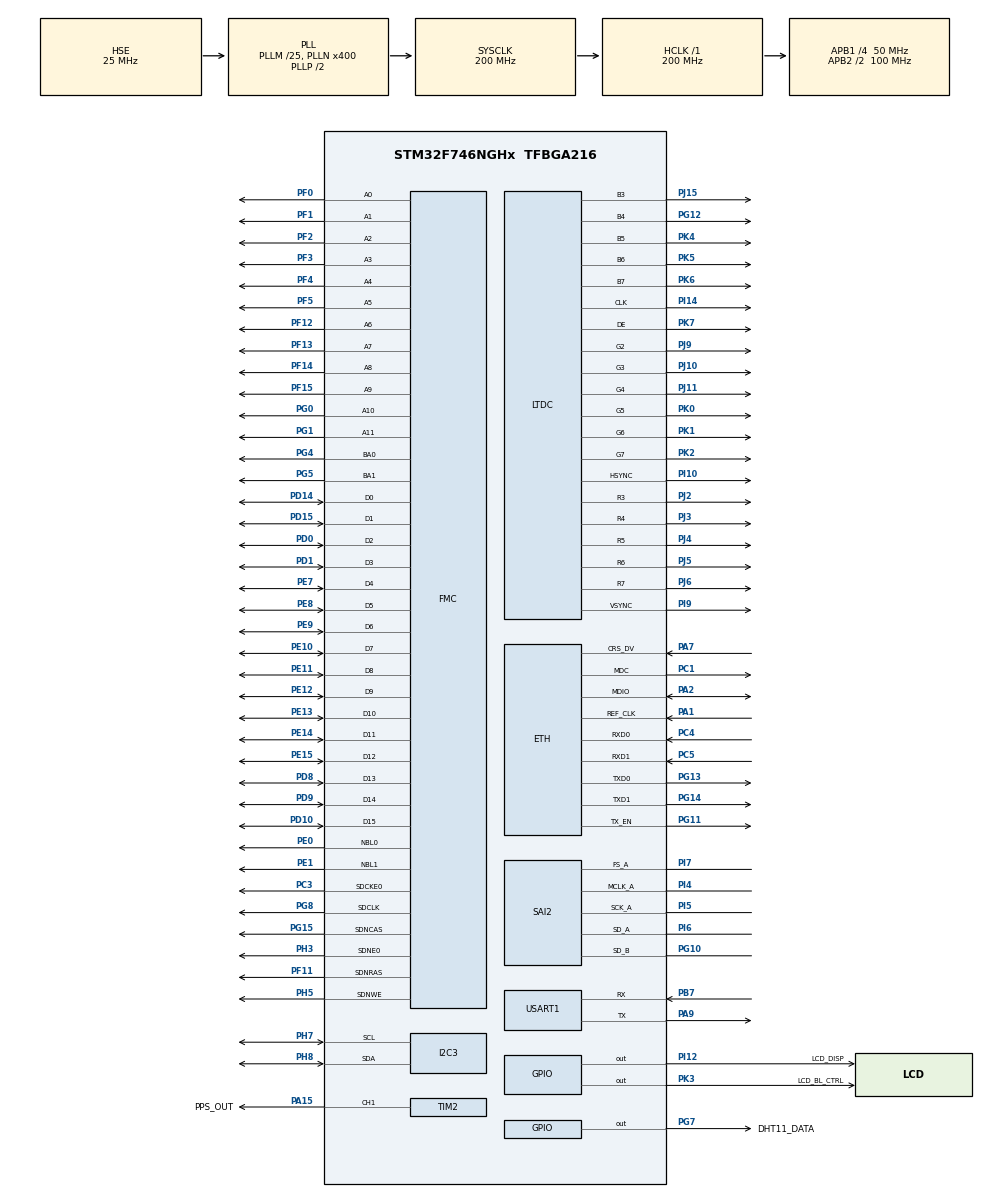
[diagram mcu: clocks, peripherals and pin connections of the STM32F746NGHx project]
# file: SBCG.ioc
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CORTEX_M7.AccessPermission_S-Cortex_Memory_Protection_Unit_Region1_Settings_S=MPU_REGION_FULL_ACCESS
CORTEX_M7.AccessPermission_S-Cortex_Memory_Protection_Unit_Region2_Settings_S=MPU_REGION_FULL_ACCESS
CORTEX_M7.BaseAddress_S-Cortex_Memory_Protection_Unit_Region1_Settings_S=0xC0000000
CORTEX_M7.BaseAddress_S-Cortex_Memory_Protection_Unit_Region2_Settings_S=0xA0000000
CORTEX_M7.DisableExec_S-Cortex_Memory_Protection_Unit_Region1_Settings_S=MPU_INSTRUCTION_ACCESS_DISABLE
CORTEX_M7.DisableExec_S-Cortex_Memory_Protection_Unit_Region2_Settings_S=MPU_INSTRUCTION_ACCESS_DISABLE
CORTEX_M7.Enable_S-Cortex_Memory_Protection_Unit_Region1_Settings_S=MPU_REGION_ENABLE
CORTEX_M7.Enable_S-Cortex_Memory_Protection_Unit_Region2_Settings_S=MPU_REGION_ENABLE
CORTEX_M7.IsBufferable_S-Cortex_Memory_Protection_Unit_Region2_Settings_S=MPU_ACCESS_BUFFERABLE
CORTEX_M7.IsShareable_S-Cortex_Memory_Protection_Unit_Region2_Settings_S=MPU_ACCESS_SHAREABLE
CORTEX_M7.Size_S-Cortex_Memory_Protection_Unit_Region1_Settings_S=MPU_REGION_SIZE_8MB
CORTEX_M7.Size_S-Cortex_Memory_Protection_Unit_Region2_Settings_S=MPU_REGION_SIZE_4KB
CORTEX_M7.TypeExtField_S-Cortex_Memory_Protection_Unit_Region1_Settings_S=MPU_TEX_LEVEL1
CORTEX_M7.default_mode_Activation=1
Dma.Request0=SAI2_B
Dma.Request1=USART1_TX
Dma.SAI2_B.0.Direction=DMA_PERIPH_TO_MEMORY
Dma.SAI2_B.0.FIFOMode=DMA_FIFOMODE_DISABLE
Dma.SAI2_B.0.Instance=DMA2_Stream6
Dma.SAI2_B.0.MemDataAlignment=DMA_MDATAALIGN_HALFWORD
Dma.SAI2_B.0.MemInc=DMA_MINC_ENABLE
Dma.SAI2_B.0.Mode=DMA_CIRCULAR
Dma.SAI2_B.0.PeriphDataAlignment=DMA_PDATAALIGN_HALFWORD
Dma.SAI2_B.0.PeriphInc=DMA_PINC_DISABLE
Dma.SAI2_B.0.Priority=DMA_PRIORITY_HIGH
Dma.USART1_TX.1.Direction=DMA_MEMORY_TO_PERIPH
Dma.USART1_TX.1.FIFOMode=DMA_FIFOMODE_DISABLE
Dma.USART1_TX.1.Instance=DMA2_Stream7
Dma.USART1_TX.1.MemDataAlignment=DMA_MDATAALIGN_BYTE
Dma.USART1_TX.1.MemInc=DMA_MINC_ENABLE
Dma.USART1_TX.1.Mode=DMA_NORMAL
Dma.USART1_TX.1.PeriphDataAlignment=DMA_PDATAALIGN_BYTE
Dma.USART1_TX.1.PeriphInc=DMA_PINC_DISABLE
Dma.USART1_TX.1.Priority=DMA_PRIORITY_LOW
ETH.MACAddr=02\:00\:00\:00\:00\:01
ETH.MediaInterface=HAL_ETH_RMII_MODE
ETH.RxBuffLen=1536
ETH.RxDescAddress=0x2004C0A0
ETH.TxDescAddress=0x2004C000
FMC.CASLatency1=FMC_SDRAM_CAS_LATENCY_3
FMC.ExitSelfRefreshDelay1=8
FMC.LoadToActiveDelay1=2
FMC.RCDDelay1=2
FMC.RPDelay1=2
FMC.ReadBurst1=FMC_SDRAM_RBURST_ENABLE
FMC.ReadPipeDelay1=FMC_SDRAM_RPIPE_DELAY_0
FMC.RowCycleDelay1=7
FMC.SDClockPeriod1=FMC_SDRAM_CLOCK_PERIOD_3
FMC.SelfRefreshTime1=5
FMC.WriteRecoveryTime1=3
I2C3.Timing=0x00C0EAFF
LTDC.ActiveH=272
LTDC.ActiveW=480
LTDC.Alpha_L0=255
LTDC.FBStartAdress_L0=0xC0000000
LTDC.HBP=13
LTDC.HFP=32
LTDC.HSync=41
LTDC.ImageHeight_L0=272
LTDC.ImageWidth_L0=480
LTDC.Layers=0
LTDC.PixelFormat_L0=LTDC_PIXEL_FORMAT_RGB565
LTDC.VSync=10
LTDC.WindowX1_L0=480
LTDC.WindowY1_L0=272
LWIP.BSP.number=1
LWIP.ETH_RX_BUFFER_CNT=4
LWIP.IP_ADDRESS=192.168.010.001
LWIP.LWIP_DHCP=0
LWIP.LWIP_TCP=0
LWIP.MEMP_NUM_UDP_PCB=10
LWIP.MEM_SIZE=4096
LWIP.NETMASK_ADDRESS=255.255.255.000
LWIP.Version=v2.1.2_Cube
LWIP0.BSP.STBoard=false
LWIP0.BSP.api=BSP_COMPONENT_DRIVER
LWIP0.BSP.component=LAN8742
LWIP0.BSP.instance=LAN8742
LWIP0.BSP.name=Driver_PHY
LWIP0.BSP.semaphore=S_LAN8742
LWIP0.BSP.solution=LAN8742
Mcu.Family=STM32F7
Mcu.Name=STM32F746NGHx
Mcu.Package=TFBGA216
NVIC.DMA2_Stream6_IRQn=true\:4\:0\:false\:false\:true\:false\:true\:true
NVIC.DMA2_Stream7_IRQn=true\:6\:0\:true\:false\:true\:false\:true\:true
NVIC.LTDC_IRQn=true\:9\:0\:true\:false\:true\:true\:true\:true
NVIC.PriorityGroup=NVIC_PRIORITYGROUP_4
NVIC.SAI2_IRQn=true\:4\:0\:true\:false\:true\:true\:true\:true
NVIC.USART1_IRQn=true\:5\:0\:true\:false\:true\:true\:true\:true
PA1.Mode=RMII
PA1.Signal=ETH_REF_CLK
PA13.Mode=Trace_Asynchronous_SW
PA13.Signal=SYS_JTMS-SWDIO
PA14.Mode=Trace_Asynchronous_SW
PA14.Signal=SYS_JTCK-SWCLK
PA15.GPIO_Label=PPS_OUT
PA15.GPIO_PuPd=GPIO_PULLDOWN
PA15.Signal=S_TIM2_CH1_ETR
PA2.Mode=RMII
PA2.Signal=ETH_MDIO
PA7.Mode=RMII
PA7.Signal=ETH_CRS_DV
PA9.Mode=Asynchronous
PA9.Signal=USART1_TX
PB3.Mode=Trace_Asynchronous_SW
PB3.Signal=SYS_JTDO-SWO
PB7.Mode=Asynchronous
PB7.Signal=USART1_RX
PC1.Mode=RMII
PC1.Signal=ETH_MDC
PC3.Mode=SdramChipSelect1_1
PC3.Signal=FMC_SDCKE0
PC4.Mode=RMII
PC4.Signal=ETH_RXD0
PC5.Mode=RMII
PC5.Signal=ETH_RXD1
PD0.Signal=FMC_D2_DA2
PD1.Signal=FMC_D3_DA3
PD10.Signal=FMC_D15_DA15
PD14.Signal=FMC_D0_DA0
PD15.Signal=FMC_D1_DA1
PD8.Signal=FMC_D13_DA13
PD9.Signal=FMC_D14_DA14
PE0.Signal=FMC_NBL0
PE1.Signal=FMC_NBL1
PE10.Signal=FMC_D7_DA7
PE11.Signal=FMC_D8_DA8
PE12.Signal=FMC_D9_DA9
PE13.Signal=FMC_D10_DA10
PE14.Signal=FMC_D11_DA11
PE15.Signal=FMC_D12_DA12
PE7.Signal=FMC_D4_DA4
PE8.Signal=FMC_D5_DA5
PE9.Signal=FMC_D6_DA6
PF0.Signal=FMC_A0
PF1.Signal=FMC_A1
PF11.Signal=FMC_SDNRAS
PF12.Signal=FMC_A6
PF13.Signal=FMC_A7
PF14.Signal=FMC_A8
PF15.Signal=FMC_A9
PF2.Signal=FMC_A2
PF3.Signal=FMC_A3
PF4.Signal=FMC_A4
PF5.Signal=FMC_A5
PG0.Signal=FMC_A10
PG1.Signal=FMC_A11
PG10.GPIO_Speed=GPIO_SPEED_FREQ_HIGH
PG10.Mode=SAI_B_SyncSlave
PG10.Signal=SAI2_SD_B
PG11.Mode=RMII
PG11.Signal=ETH_TX_EN
PG12.GPIO_Speed=GPIO_SPEED_FREQ_VERY_HIGH
PG12.Mode=RGB565
PG12.Signal=LTDC_B4
PG13.Mode=RMII
PG13.Signal=ETH_TXD0
PG14.Mode=RMII
PG14.Signal=ETH_TXD1
PG15.Signal=FMC_SDNCAS
PG4.Signal=FMC_A14_BA0
PG5.Signal=FMC_A15_BA1
PG7.GPIO_Label=DHT11_DATA
PG7.GPIO_ModeDefaultOutputPP=GPIO_MODE_OUTPUT_OD
PG7.GPIO_PuPd=GPIO_NOPULL
PG7.PinState=GPIO_PIN_SET
PG7.Signal=GPIO_Output
PG8.Signal=FMC_SDCLK
PH0/OSC_IN.Mode=HSE-External-Clock-Source
PH0/OSC_IN.Signal=RCC_OSC_IN
PH1/OSC_OUT.Mode=HSE-External-Clock-Source
PH1/OSC_OUT.Signal=RCC_OSC_OUT
PH3.Mode=SdramChipSelect1_1
PH3.Signal=FMC_SDNE0
PH5.Signal=FMC_SDNWE
PH7.Mode=I2C
PH7.Signal=I2C3_SCL
PH8.Mode=I2C
PH8.Signal=I2C3_SDA
PI10.GPIO_Speed=GPIO_SPEED_FREQ_VERY_HIGH
PI10.Mode=RGB565
PI10.Signal=LTDC_HSYNC
PI12.GPIO_Label=LCD_DISP
PI12.Signal=GPIO_Output
PI14.GPIO_Speed=GPIO_SPEED_FREQ_VERY_HIGH
PI14.Mode=RGB565
PI14.Signal=LTDC_CLK
PI4.GPIO_Speed=GPIO_SPEED_FREQ_VERY_HIGH
PI4.Mode=SAI_A_MasterWithClock
PI4.Signal=SAI2_MCLK_A
PI5.GPIO_Speed=GPIO_SPEED_FREQ_VERY_HIGH
PI5.Mode=SAI_A_MasterWithClock
PI5.Signal=SAI2_SCK_A
PI6.GPIO_Speed=GPIO_SPEED_FREQ_VERY_HIGH
PI6.Mode=SAI_A_MasterWithClock
PI6.Signal=SAI2_SD_A
PI7.GPIO_Speed=GPIO_SPEED_FREQ_VERY_HIGH
PI7.Mode=SAI_A_MasterWithClock
PI7.Signal=SAI2_FS_A
PI9.GPIO_Speed=GPIO_SPEED_FREQ_VERY_HIGH
PI9.Mode=RGB565
PI9.Signal=LTDC_VSYNC
PJ10.GPIO_Speed=GPIO_SPEED_FREQ_VERY_HIGH
PJ10.Mode=RGB565
PJ10.Signal=LTDC_G3
PJ11.GPIO_Speed=GPIO_SPEED_FREQ_VERY_HIGH
PJ11.Mode=RGB565
PJ11.Signal=LTDC_G4
PJ15.GPIO_Speed=GPIO_SPEED_FREQ_VERY_HIGH
PJ15.Mode=RGB565
PJ15.Signal=LTDC_B3
PJ2.GPIO_Speed=GPIO_SPEED_FREQ_VERY_HIGH
PJ2.Mode=RGB565
PJ2.Signal=LTDC_R3
PJ3.GPIO_Speed=GPIO_SPEED_FREQ_VERY_HIGH
PJ3.Mode=RGB565
PJ3.Signal=LTDC_R4
PJ4.GPIO_Speed=GPIO_SPEED_FREQ_VERY_HIGH
PJ4.Mode=RGB565
PJ4.Signal=LTDC_R5
PJ5.GPIO_Speed=GPIO_SPEED_FREQ_VERY_HIGH
PJ5.Mode=RGB565
PJ5.Signal=LTDC_R6
PJ6.GPIO_Speed=GPIO_SPEED_FREQ_VERY_HIGH
PJ6.Mode=RGB565
PJ6.Signal=LTDC_R7
PJ9.GPIO_Speed=GPIO_SPEED_FREQ_VERY_HIGH
PJ9.Mode=RGB565
PJ9.Signal=LTDC_G2
PK0.GPIO_Speed=GPIO_SPEED_FREQ_VERY_HIGH
PK0.Mode=RGB565
PK0.Signal=LTDC_G5
PK1.GPIO_Speed=GPIO_SPEED_FREQ_VERY_HIGH
PK1.Mode=RGB565
PK1.Signal=LTDC_G6
PK2.GPIO_Speed=GPIO_SPEED_FREQ_VERY_HIGH
PK2.Mode=RGB565
PK2.Signal=LTDC_G7
PK3.GPIO_Label=LCD_BL_CTRL
PK3.Signal=GPIO_Output
PK4.GPIO_Speed=GPIO_SPEED_FREQ_VERY_HIGH
PK4.Mode=RGB565
PK4.Signal=LTDC_B5
PK5.GPIO_Speed=GPIO_SPEED_FREQ_VERY_HIGH
PK5.Mode=RGB565
PK5.Signal=LTDC_B6
PK6.GPIO_Speed=GPIO_SPEED_FREQ_VERY_HIGH
PK6.Mode=RGB565
PK6.Signal=LTDC_B7
PK7.GPIO_Speed=GPIO_SPEED_FREQ_VERY_HIGH
PK7.Mode=RGB565
PK7.Signal=LTDC_DE
ProjectManager.HeapSize=0x200
ProjectManager.StackSize=0x400
ProjectManager.TargetToolchain=CMake
RCC.AHBFreq_Value=200000000
RCC.APB1CLKDivider=RCC_HCLK_DIV4
RCC.APB1Freq_Value=50000000
RCC.APB1TimFreq_Value=100000000
RCC.APB2CLKDivider=RCC_HCLK_DIV2
RCC.APB2Freq_Value=100000000
RCC.APB2TimFreq_Value=200000000
RCC.CortexFreq_Value=200000000
RCC.HCLKFreq_Value=200000000
RCC.HSE_VALUE=25000000
RCC.HSI_VALUE=16000000
RCC.LSE_VALUE=32768
RCC.PLLI2SN=344
RCC.PLLI2SQ=7
RCC.PLLM=25
RCC.PLLN=400
RCC.PLLSAIR=5
RCC.PLLSAIRDiv=RCC_PLLSAIDIVR_4
RCC.PLLSourceVirtual=RCC_PLLSOURCE_HSE
RCC.SAI2CLockSelection=RCC_SAI2CLKSOURCE_PLLI2S
RCC.SYSCLKFreq_VALUE=200000000
RCC.SYSCLKSource=RCC_SYSCLKSOURCE_PLLCLK
RCC.USBFreq_Value=200000000
RCC.VCOOutputFreq_Value=400000000
SAI2.ActiveFrameLength-SAI_A_MasterWithClock=32
SAI2.ActiveFrameLength-SAI_B_SyncSlave=32
SAI2.AudioFrequency-SAI_A_MasterWithClock=SAI_AUDIO_FREQUENCY_48K
SAI2.AudioMode-SAI_A_MasterWithClock=SAI_MODEMASTER_RX
SAI2.ClockStrobing-SAI_A_MasterWithClock=SAI_CLOCKSTROBING_RISINGEDGE
SAI2.ClockStrobing-SAI_B_SyncSlave=SAI_CLOCKSTROBING_RISINGEDGE
SAI2.DataSize-SAI_A_MasterWithClock=SAI_DATASIZE_16
SAI2.DataSize-SAI_B_SyncSlave=SAI_DATASIZE_16
SAI2.ErrorAudioFreq-SAI_A_MasterWithClock=-0.01 %
SAI2.FIFOThreshold-SAI_A_MasterWithClock=SAI_FIFOTHRESHOLD_1QF
SAI2.FIFOThreshold-SAI_B_SyncSlave=SAI_FIFOTHRESHOLD_1QF
SAI2.FSDefinition-SAI_A_MasterWithClock=SAI_FS_CHANNEL_IDENTIFICATION
SAI2.FSDefinition-SAI_B_SyncSlave=SAI_FS_CHANNEL_IDENTIFICATION
SAI2.FSOffset-SAI_A_MasterWithClock=SAI_FS_BEFOREFIRSTBIT
SAI2.FSOffset-SAI_B_SyncSlave=SAI_FS_BEFOREFIRSTBIT
SAI2.FrameLength-SAI_A_MasterWithClock=64
SAI2.FrameLength-SAI_B_SyncSlave=64
SAI2.Instance-SAI_A_MasterWithClock=SAI$Index_Block_A
SAI2.Instance-SAI_B_SyncSlave=SAI$Index_Block_B
SAI2.MClockEnable-SAI_A_MasterWithClock=SAI_MASTERCLOCK_ENABLE
SAI2.OutputDrive-SAI_A_MasterWithClock=SAI_OUTPUTDRIVE_ENABLE
SAI2.RealAudioFreq-SAI_A_MasterWithClock=47.991 KHz
SAI2.SlotActive-SAI_A_MasterWithClock=0x0000000A
SAI2.SlotActive-SAI_B_SyncSlave=0x0000000A
SAI2.SlotNumber-SAI_A_MasterWithClock=4
SAI2.SlotNumber-SAI_B_SyncSlave=4
SAI2.VirtualMode-SAI_A_MasterWithClock=VM_MASTER
SAI2.VirtualMode-SAI_B_SyncSlave=VM_SLAVE
SAI2.VirtualSlotActive-SAI_A_MasterWithClock=SAI_SLOT_USERSETTING
SAI2.VirtualSlotActive-SAI_B_SyncSlave=SAI_SLOT_USERSETTING
SAI2.VirtualSlotActive0-SAI_B_SyncSlave=false
SAI2.VirtualSlotActive1-SAI_A_MasterWithClock=true
SAI2.VirtualSlotActive1-SAI_B_SyncSlave=true
SAI2.VirtualSlotActive2-SAI_B_SyncSlave=false
SAI2.VirtualSlotActive3-SAI_A_MasterWithClock=true
SAI2.VirtualSlotActive3-SAI_B_SyncSlave=true
SH.FMC_A0.0=FMC_A0,12b-sda1
SH.FMC_A1.0=FMC_A1,12b-sda1
SH.FMC_A10.0=FMC_A10,12b-sda1
SH.FMC_A11.0=FMC_A11,12b-sda1
SH.FMC_A14_BA0.0=FMC_BA0,FourSdramBanks1
SH.FMC_A15_BA1.0=FMC_BA1,FourSdramBanks1
SH.FMC_A2.0=FMC_A2,12b-sda1
SH.FMC_A3.0=FMC_A3,12b-sda1
SH.FMC_A4.0=FMC_A4,12b-sda1
SH.FMC_A5.0=FMC_A5,12b-sda1
SH.FMC_A6.0=FMC_A6,12b-sda1
SH.FMC_A7.0=FMC_A7,12b-sda1
SH.FMC_A8.0=FMC_A8,12b-sda1
SH.FMC_A9.0=FMC_A9,12b-sda1
SH.FMC_D0_DA0.0=FMC_D0,sd-16b-d1
SH.FMC_D10_DA10.0=FMC_D10,sd-16b-d1
SH.FMC_D11_DA11.0=FMC_D11,sd-16b-d1
SH.FMC_D12_DA12.0=FMC_D12,sd-16b-d1
SH.FMC_D13_DA13.0=FMC_D13,sd-16b-d1
SH.FMC_D14_DA14.0=FMC_D14,sd-16b-d1
SH.FMC_D15_DA15.0=FMC_D15,sd-16b-d1
SH.FMC_D1_DA1.0=FMC_D1,sd-16b-d1
SH.FMC_D2_DA2.0=FMC_D2,sd-16b-d1
SH.FMC_D3_DA3.0=FMC_D3,sd-16b-d1
SH.FMC_D4_DA4.0=FMC_D4,sd-16b-d1
SH.FMC_D5_DA5.0=FMC_D5,sd-16b-d1
SH.FMC_D6_DA6.0=FMC_D6,sd-16b-d1
SH.FMC_D7_DA7.0=FMC_D7,sd-16b-d1
SH.FMC_D8_DA8.0=FMC_D8,sd-16b-d1
SH.FMC_D9_DA9.0=FMC_D9,sd-16b-d1
SH.FMC_NBL0.0=FMC_NBL0,Sd2ByteEnable1
SH.FMC_NBL1.0=FMC_NBL1,Sd2ByteEnable1
SH.FMC_SDCLK.0=FMC_SDCLK,12b-sda1
SH.FMC_SDNCAS.0=FMC_SDNCAS,12b-sda1
SH.FMC_SDNRAS.0=FMC_SDNRAS,12b-sda1
SH.FMC_SDNWE.0=FMC_SDNWE,12b-sda1
SH.S_TIM2_CH1_ETR.0=TIM2_CH1,PWM Generation1 CH1
STMicroelectronics.X-CUBE-TOUCHGFX.4.26.1.ApplicationCcGraphicsJjApplication=TouchGFXOoGenerator
STMicroelectronics.X-CUBE-TOUCHGFX.4.26.1.tgfx_address1=0xC0000000
STMicroelectronics.X-CUBE-TOUCHGFX.4.26.1.tgfx_address2=0xC0040000
STMicroelectronics.X-CUBE-TOUCHGFX.4.26.1.tgfx_buffering_strategy=Double
STMicroelectronics.X-CUBE-TOUCHGFX.4.26.1.tgfx_display_interface=disp_ltdc
STMicroelectronics.X-CUBE-TOUCHGFX.4.26.1.tgfx_location=By Address
STMicroelectronics.X-CUBE-TOUCHGFX.4.26.1.tgfx_vsync=vsync_ltdc
STMicroelectronics.X-CUBE-TOUCHGFX.4.26.1_IsPackSelfContextualization=true
TIM2.Channel-PWM\ Generation1\ CH1=TIM_CHANNEL_1
TIM2.Prescaler=99
TIM2.Pulse-PWM\ Generation1\ CH1=100
TIM2.TIM2_ITR1_REMAP=TIM_TIM2_ETH_PTP
TIM2.TIM_MasterSlaveMode=TIM_MASTERSLAVEMODE_ENABLE
USART1.VirtualMode-Asynchronous=VM_ASYNC
VP_CRC_VS_CRC.Mode=CRC_Activate
VP_LWIP_VS_Enabled.Mode=Enabled
VP_STMicroelectronics.X-CUBE-TOUCHGFX_VS_GraphicsJjApplication_4.26.1.Mode=GraphicsJjApplication
VP_TIM2_VS_ClockSourceINT.Mode=Internal
VP_TIM2_VS_ClockSourceITR.Mode=TriggerSource_ITR1
VP_TIM2_VS_ControllerModeReset.Mode=Reset Mode
board=custom

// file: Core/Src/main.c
/* USER CODE BEGIN Header */
/**
  ******************************************************************************
  * @file           : main.c
  * @brief          : Main program body
  ******************************************************************************
  * @attention
  *
  * Copyright (c) 2026 STMicroelectronics.
  * All rights reserved.
  *
  * This software is licensed under terms that can be found in the LICENSE file
  * in the root directory of this software component.
  * If no LICENSE file comes with this software, it is provided AS-IS.
  *
  ******************************************************************************
  */
/* USER CODE END Header */
#include "main.h"
#include "lwip.h"
#include "app_touchgfx.h"

/* USER CODE BEGIN Includes */
#include "app_main.h"
#ifdef SBCG_STACK_DIAGNOSTIC
#include "BSP/bsp_stack_diag.h"
#endif
#ifdef SBCG_USE_RESET_DIAGNOSTIC
#include "BSP/bsp_reset.h"
#endif
/* USER CODE END Includes */

CRC_HandleTypeDef hcrc;

I2C_HandleTypeDef hi2c3;

LTDC_HandleTypeDef hltdc;

SAI_HandleTypeDef hsai_BlockA2;
SAI_HandleTypeDef hsai_BlockB2;
DMA_HandleTypeDef hdma_sai2_b;

TIM_HandleTypeDef htim2;

UART_HandleTypeDef huart1;
DMA_HandleTypeDef hdma_usart1_tx;

SDRAM_HandleTypeDef hsdram1;

void SystemClock_Config(void);
void PeriphCommonClock_Config(void);
static void MPU_Config(void);
static void MX_GPIO_Init(void);
static void MX_DMA_Init(void);
static void MX_USART1_UART_Init(void);
static void MX_I2C3_Init(void);
static void MX_SAI2_Init(void);
static void MX_TIM2_Init(void);
static void MX_FMC_Init(void);
static void MX_CRC_Init(void);

int main(void)
{

  /* USER CODE BEGIN 1 */
#ifdef SBCG_STACK_DIAGNOSTIC
  /* 在HAL启动中断前涂写MSP预留区，跳过当前main栈帧。 */
  BSP_StackDiag_Paint();
#endif
#ifdef SBCG_USE_RESET_DIAGNOSTIC
  /* 在HAL/时钟初始化前保存并清除累计复位状态，不改变时钟或引脚配置。 */
  BSP_Reset_Capture();
#endif
  /* USER CODE END 1 */

  /* MPU Configuration--------------------------------------------------------*/
  MPU_Config();

  /* MCU Configuration--------------------------------------------------------*/

  /* Reset of all peripherals, Initializes the Flash interface and the Systick. */
  HAL_Init();

  /* Configure the system clock */
  SystemClock_Config();

  /* Configure the peripherals common clocks */
  PeriphCommonClock_Config();

  /* Initialize all configured peripherals */
  MX_GPIO_Init();
  MX_DMA_Init();
  MX_USART1_UART_Init();
  MX_I2C3_Init();
  MX_LWIP_Init();
  MX_SAI2_Init();
  MX_TIM2_Init();
  MX_FMC_Init();
  MX_CRC_Init();
  /* USER CODE BEGIN 2 */
  App_Init();
  /* USER CODE END 2 */

  /* Infinite loop */
  while (1)
  {

  MX_TouchGFX_Process();
    /* USER CODE BEGIN 3 */
    App_Process();
  }
  /* USER CODE END 3 */
}

void SystemClock_Config(void)
{
  RCC_OscInitTypeDef RCC_OscInitStruct = {0};
  RCC_ClkInitTypeDef RCC_ClkInitStruct = {0};

  /** Configure the main internal regulator output voltage
  */
  __HAL_RCC_PWR_CLK_ENABLE();
  __HAL_PWR_VOLTAGESCALING_CONFIG(PWR_REGULATOR_VOLTAGE_SCALE1);

  /** Initializes the RCC Oscillators according to the specified parameters
  * in the RCC_OscInitTypeDef structure.
  */
  RCC_OscInitStruct.OscillatorType = RCC_OSCILLATORTYPE_HSE;
  RCC_OscInitStruct.HSEState = RCC_HSE_BYPASS;
  RCC_OscInitStruct.PLL.PLLState = RCC_PLL_ON;
  RCC_OscInitStruct.PLL.PLLSource = RCC_PLLSOURCE_HSE;
  RCC_OscInitStruct.PLL.PLLM = 25;
  RCC_OscInitStruct.PLL.PLLN = 400;
  RCC_OscInitStruct.PLL.PLLP = RCC_PLLP_DIV2;
  RCC_OscInitStruct.PLL.PLLQ = 2;
  if (HAL_RCC_OscConfig(&RCC_OscInitStruct) != HAL_OK)
  {
    Error_Handler();
  }

  /** Activate the Over-Drive mode
  */
  if (HAL_PWREx_EnableOverDrive() != HAL_OK)
  {
    Error_Handler();
  }

  /** Initializes the CPU, AHB and APB buses clocks
  */
  RCC_ClkInitStruct.ClockType = RCC_CLOCKTYPE_HCLK|RCC_CLOCKTYPE_SYSCLK
                              |RCC_CLOCKTYPE_PCLK1|RCC_CLOCKTYPE_PCLK2;
  RCC_ClkInitStruct.SYSCLKSource = RCC_SYSCLKSOURCE_PLLCLK;
  RCC_ClkInitStruct.AHBCLKDivider = RCC_SYSCLK_DIV1;
  RCC_ClkInitStruct.APB1CLKDivider = RCC_HCLK_DIV4;
  RCC_ClkInitStruct.APB2CLKDivider = RCC_HCLK_DIV2;

  if (HAL_RCC_ClockConfig(&RCC_ClkInitStruct, FLASH_LATENCY_6) != HAL_OK)
  {
    Error_Handler();
  }
}

void PeriphCommonClock_Config(void)
{
  RCC_PeriphCLKInitTypeDef PeriphClkInitStruct = {0};

  /** Initializes the peripherals clock
  */
  PeriphClkInitStruct.PeriphClockSelection = RCC_PERIPHCLK_SAI2;
  PeriphClkInitStruct.PLLI2S.PLLI2SN = 344;
  PeriphClkInitStruct.PLLI2S.PLLI2SP = RCC_PLLP_DIV2;
  PeriphClkInitStruct.PLLI2S.PLLI2SR = 2;
  PeriphClkInitStruct.PLLI2S.PLLI2SQ = 7;
  PeriphClkInitStruct.PLLI2SDivQ = 1;
  PeriphClkInitStruct.Sai2ClockSelection = RCC_SAI2CLKSOURCE_PLLI2S;
  if (HAL_RCCEx_PeriphCLKConfig(&PeriphClkInitStruct) != HAL_OK)
  {
    Error_Handler();
  }
}

static void MX_CRC_Init(void)
{

  hcrc.Instance = CRC;
  hcrc.Init.DefaultPolynomialUse = DEFAULT_POLYNOMIAL_ENABLE;
  hcrc.Init.DefaultInitValueUse = DEFAULT_INIT_VALUE_ENABLE;
  hcrc.Init.InputDataInversionMode = CRC_INPUTDATA_INVERSION_NONE;
  hcrc.Init.OutputDataInversionMode = CRC_OUTPUTDATA_INVERSION_DISABLE;
  hcrc.InputDataFormat = CRC_INPUTDATA_FORMAT_BYTES;
  if (HAL_CRC_Init(&hcrc) != HAL_OK)
  {
    Error_Handler();
  }

}

static void MX_I2C3_Init(void)
{

  hi2c3.Instance = I2C3;
  hi2c3.Init.Timing = 0x00C0EAFF;
  hi2c3.Init.OwnAddress1 = 0;
  hi2c3.Init.AddressingMode = I2C_ADDRESSINGMODE_7BIT;
  hi2c3.Init.DualAddressMode = I2C_DUALADDRESS_DISABLE;
  hi2c3.Init.OwnAddress2 = 0;
  hi2c3.Init.OwnAddress2Masks = I2C_OA2_NOMASK;
  hi2c3.Init.GeneralCallMode = I2C_GENERALCALL_DISABLE;
  hi2c3.Init.NoStretchMode = I2C_NOSTRETCH_DISABLE;
  if (HAL_I2C_Init(&hi2c3) != HAL_OK)
  {
    Error_Handler();
  }

  /** Configure Analogue filter
  */
  if (HAL_I2CEx_ConfigAnalogFilter(&hi2c3, I2C_ANALOGFILTER_ENABLE) != HAL_OK)
  {
    Error_Handler();
  }

  /** Configure Digital filter
  */
  if (HAL_I2CEx_ConfigDigitalFilter(&hi2c3, 0) != HAL_OK)
  {
    Error_Handler();
  }

}

void MX_LTDC_Init(void)
{

  LTDC_LayerCfgTypeDef pLayerCfg = {0};

  hltdc.Instance = LTDC;
  hltdc.Init.HSPolarity = LTDC_HSPOLARITY_AL;
  hltdc.Init.VSPolarity = LTDC_VSPOLARITY_AL;
  hltdc.Init.DEPolarity = LTDC_DEPOLARITY_AL;
  hltdc.Init.PCPolarity = LTDC_PCPOLARITY_IPC;
  hltdc.Init.HorizontalSync = 40;
  hltdc.Init.VerticalSync = 9;
  hltdc.Init.AccumulatedHBP = 53;
  hltdc.Init.AccumulatedVBP = 11;
  hltdc.Init.AccumulatedActiveW = 533;
  hltdc.Init.AccumulatedActiveH = 283;
  hltdc.Init.TotalWidth = 565;
  hltdc.Init.TotalHeigh = 285;
  hltdc.Init.Backcolor.Blue = 0;
  hltdc.Init.Backcolor.Green = 0;
  hltdc.Init.Backcolor.Red = 0;
  if (HAL_LTDC_Init(&hltdc) != HAL_OK)
  {
    Error_Handler();
  }
  pLayerCfg.WindowX0 = 0;
  pLayerCfg.WindowX1 = 480;
  pLayerCfg.WindowY0 = 0;
  pLayerCfg.WindowY1 = 272;
  pLayerCfg.PixelFormat = LTDC_PIXEL_FORMAT_RGB565;
  pLayerCfg.Alpha = 255;
  pLayerCfg.Alpha0 = 0;
  pLayerCfg.BlendingFactor1 = LTDC_BLENDING_FACTOR1_CA;
  pLayerCfg.BlendingFactor2 = LTDC_BLENDING_FACTOR2_CA;
  pLayerCfg.FBStartAdress = 0xC0000000;
  pLayerCfg.ImageWidth = 480;
  pLayerCfg.ImageHeight = 272;
  pLayerCfg.Backcolor.Blue = 0;
  pLayerCfg.Backcolor.Green = 0;
  pLayerCfg.Backcolor.Red = 0;
  if (HAL_LTDC_ConfigLayer(&hltdc, &pLayerCfg, 0) != HAL_OK)
  {
    Error_Handler();
  }

}

static void MX_SAI2_Init(void)
{

  hsai_BlockA2.Instance = SAI2_Block_A;
  hsai_BlockA2.Init.Protocol = SAI_FREE_PROTOCOL;
  hsai_BlockA2.Init.AudioMode = SAI_MODEMASTER_RX;
  hsai_BlockA2.Init.DataSize = SAI_DATASIZE_16;
  hsai_BlockA2.Init.FirstBit = SAI_FIRSTBIT_MSB;
  hsai_BlockA2.Init.ClockStrobing = SAI_CLOCKSTROBING_RISINGEDGE;
  hsai_BlockA2.Init.Synchro = SAI_ASYNCHRONOUS;
  hsai_BlockA2.Init.OutputDrive = SAI_OUTPUTDRIVE_ENABLE;
  hsai_BlockA2.Init.NoDivider = SAI_MASTERDIVIDER_ENABLE;
  hsai_BlockA2.Init.FIFOThreshold = SAI_FIFOTHRESHOLD_1QF;
  hsai_BlockA2.Init.AudioFrequency = SAI_AUDIO_FREQUENCY_48K;
  hsai_BlockA2.Init.SynchroExt = SAI_SYNCEXT_DISABLE;
  hsai_BlockA2.Init.MonoStereoMode = SAI_STEREOMODE;
  hsai_BlockA2.Init.CompandingMode = SAI_NOCOMPANDING;
  hsai_BlockA2.FrameInit.FrameLength = 64;
  hsai_BlockA2.FrameInit.ActiveFrameLength = 32;
  hsai_BlockA2.FrameInit.FSDefinition = SAI_FS_CHANNEL_IDENTIFICATION;
  hsai_BlockA2.FrameInit.FSPolarity = SAI_FS_ACTIVE_LOW;
  hsai_BlockA2.FrameInit.FSOffset = SAI_FS_BEFOREFIRSTBIT;
  hsai_BlockA2.SlotInit.FirstBitOffset = 0;
  hsai_BlockA2.SlotInit.SlotSize = SAI_SLOTSIZE_DATASIZE;
  hsai_BlockA2.SlotInit.SlotNumber = 4;
  hsai_BlockA2.SlotInit.SlotActive = 0x0000000A;
  if (HAL_SAI_Init(&hsai_BlockA2) != HAL_OK)
  {
    Error_Handler();
  }
  hsai_BlockB2.Instance = SAI2_Block_B;
  hsai_BlockB2.Init.Protocol = SAI_FREE_PROTOCOL;
  hsai_BlockB2.Init.AudioMode = SAI_MODESLAVE_RX;
  hsai_BlockB2.Init.DataSize = SAI_DATASIZE_16;
  hsai_BlockB2.Init.FirstBit = SAI_FIRSTBIT_MSB;
  hsai_BlockB2.Init.ClockStrobing = SAI_CLOCKSTROBING_RISINGEDGE;
  hsai_BlockB2.Init.Synchro = SAI_SYNCHRONOUS;
  hsai_BlockB2.Init.OutputDrive = SAI_OUTPUTDRIVE_DISABLE;
  hsai_BlockB2.Init.FIFOThreshold = SAI_FIFOTHRESHOLD_1QF;
  hsai_BlockB2.Init.SynchroExt = SAI_SYNCEXT_DISABLE;
  hsai_BlockB2.Init.MonoStereoMode = SAI_STEREOMODE;
  hsai_BlockB2.Init.CompandingMode = SAI_NOCOMPANDING;
  hsai_BlockB2.Init.TriState = SAI_OUTPUT_NOTRELEASED;
  hsai_BlockB2.FrameInit.FrameLength = 64;
  hsai_BlockB2.FrameInit.ActiveFrameLength = 32;
  hsai_BlockB2.FrameInit.FSDefinition = SAI_FS_CHANNEL_IDENTIFICATION;
  hsai_BlockB2.FrameInit.FSPolarity = SAI_FS_ACTIVE_LOW;
  hsai_BlockB2.FrameInit.FSOffset = SAI_FS_BEFOREFIRSTBIT;
  hsai_BlockB2.SlotInit.FirstBitOffset = 0;
  hsai_BlockB2.SlotInit.SlotSize = SAI_SLOTSIZE_DATASIZE;
  hsai_BlockB2.SlotInit.SlotNumber = 4;
  hsai_BlockB2.SlotInit.SlotActive = 0x0000000A;
  if (HAL_SAI_Init(&hsai_BlockB2) != HAL_OK)
  {
    Error_Handler();
  }

}

static void MX_TIM2_Init(void)
{

  TIM_ClockConfigTypeDef sClockSourceConfig = {0};
  TIM_SlaveConfigTypeDef sSlaveConfig = {0};
  TIM_MasterConfigTypeDef sMasterConfig = {0};
  TIM_OC_InitTypeDef sConfigOC = {0};

  htim2.Instance = TIM2;
  htim2.Init.Prescaler = 99;
  htim2.Init.CounterMode = TIM_COUNTERMODE_UP;
  htim2.Init.Period = 4294967295;
  htim2.Init.ClockDivision = TIM_CLOCKDIVISION_DIV1;
  htim2.Init.AutoReloadPreload = TIM_AUTORELOAD_PRELOAD_DISABLE;
  if (HAL_TIM_Base_Init(&htim2) != HAL_OK)
  {
    Error_Handler();
  }
  sClockSourceConfig.ClockSource = TIM_CLOCKSOURCE_INTERNAL;
  if (HAL_TIM_ConfigClockSource(&htim2, &sClockSourceConfig) != HAL_OK)
  {
    Error_Handler();
  }
  if (HAL_TIM_PWM_Init(&htim2) != HAL_OK)
  {
    Error_Handler();
  }
  sSlaveConfig.SlaveMode = TIM_SLAVEMODE_RESET;
  sSlaveConfig.InputTrigger = TIM_TS_ITR1;
  if (HAL_TIM_SlaveConfigSynchro(&htim2, &sSlaveConfig) != HAL_OK)
  {
    Error_Handler();
  }
  sMasterConfig.MasterOutputTrigger = TIM_TRGO_RESET;
  sMasterConfig.MasterSlaveMode = TIM_MASTERSLAVEMODE_ENABLE;
  if (HAL_TIMEx_MasterConfigSynchronization(&htim2, &sMasterConfig) != HAL_OK)
  {
    Error_Handler();
  }
  if (HAL_TIMEx_RemapConfig(&htim2, TIM_TIM2_ETH_PTP) != HAL_OK)
  {
    Error_Handler();
  }
  sConfigOC.OCMode = TIM_OCMODE_PWM1;
  sConfigOC.Pulse = 100;
  sConfigOC.OCPolarity = TIM_OCPOLARITY_HIGH;
  sConfigOC.OCFastMode = TIM_OCFAST_DISABLE;
  if (HAL_TIM_PWM_ConfigChannel(&htim2, &sConfigOC, TIM_CHANNEL_1) != HAL_OK)
  {
    Error_Handler();
  }
  HAL_TIM_MspPostInit(&htim2);

}

static void MX_USART1_UART_Init(void)
{

  huart1.Instance = USART1;
  huart1.Init.BaudRate = 115200;
  huart1.Init.WordLength = UART_WORDLENGTH_8B;
  huart1.Init.StopBits = UART_STOPBITS_1;
  huart1.Init.Parity = UART_PARITY_NONE;
  huart1.Init.Mode = UART_MODE_TX_RX;
  huart1.Init.HwFlowCtl = UART_HWCONTROL_NONE;
  huart1.Init.OverSampling = UART_OVERSAMPLING_16;
  huart1.Init.OneBitSampling = UART_ONE_BIT_SAMPLE_DISABLE;
  huart1.AdvancedInit.AdvFeatureInit = UART_ADVFEATURE_NO_INIT;
  if (HAL_UART_Init(&huart1) != HAL_OK)
  {
    Error_Handler();
  }

}

static void MX_DMA_Init(void)
{

  /* DMA controller clock enable */
  __HAL_RCC_DMA2_CLK_ENABLE();

  /* DMA interrupt init */
  /* DMA2_Stream6_IRQn interrupt configuration */
  HAL_NVIC_SetPriority(DMA2_Stream6_IRQn, 4, 0);
  HAL_NVIC_EnableIRQ(DMA2_Stream6_IRQn);
  /* DMA2_Stream7_IRQn interrupt configuration */
  HAL_NVIC_SetPriority(DMA2_Stream7_IRQn, 6, 0);
  HAL_NVIC_EnableIRQ(DMA2_Stream7_IRQn);

}

/* FMC initialization function */
static void MX_FMC_Init(void)
{

  FMC_SDRAM_TimingTypeDef SdramTiming = {0};

  /** Perform the SDRAM1 memory initialization sequence
  */
  hsdram1.Instance = FMC_SDRAM_DEVICE;
  /* hsdram1.Init */
  hsdram1.Init.SDBank = FMC_SDRAM_BANK1;
  hsdram1.Init.ColumnBitsNumber = FMC_SDRAM_COLUMN_BITS_NUM_8;
  hsdram1.Init.RowBitsNumber = FMC_SDRAM_ROW_BITS_NUM_12;
  hsdram1.Init.MemoryDataWidth = FMC_SDRAM_MEM_BUS_WIDTH_16;
  hsdram1.Init.InternalBankNumber = FMC_SDRAM_INTERN_BANKS_NUM_4;
  hsdram1.Init.CASLatency = FMC_SDRAM_CAS_LATENCY_3;
  hsdram1.Init.WriteProtection = FMC_SDRAM_WRITE_PROTECTION_DISABLE;
  hsdram1.Init.SDClockPeriod = FMC_SDRAM_CLOCK_PERIOD_3;
  hsdram1.Init.ReadBurst = FMC_SDRAM_RBURST_ENABLE;
  hsdram1.Init.ReadPipeDelay = FMC_SDRAM_RPIPE_DELAY_0;
  /* SdramTiming */
  SdramTiming.LoadToActiveDelay = 2;
  SdramTiming.ExitSelfRefreshDelay = 8;
  SdramTiming.SelfRefreshTime = 5;
  SdramTiming.RowCycleDelay = 7;
  SdramTiming.WriteRecoveryTime = 3;
  SdramTiming.RPDelay = 2;
  SdramTiming.RCDDelay = 2;

  if (HAL_SDRAM_Init(&hsdram1, &SdramTiming) != HAL_OK)
  {
    Error_Handler( );
  }

}

static void MX_GPIO_Init(void)
{
  GPIO_InitTypeDef GPIO_InitStruct = {0};

  /* GPIO Ports Clock Enable */
  __HAL_RCC_GPIOG_CLK_ENABLE();
  __HAL_RCC_GPIOE_CLK_ENABLE();
  __HAL_RCC_GPIOB_CLK_ENABLE();
  __HAL_RCC_GPIOA_CLK_ENABLE();
  __HAL_RCC_GPIOD_CLK_ENABLE();
  __HAL_RCC_GPIOI_CLK_ENABLE();
  __HAL_RCC_GPIOK_CLK_ENABLE();
  __HAL_RCC_GPIOF_CLK_ENABLE();
  __HAL_RCC_GPIOJ_CLK_ENABLE();
  __HAL_RCC_GPIOH_CLK_ENABLE();
  __HAL_RCC_GPIOC_CLK_ENABLE();

  /*Configure GPIO pin Output Level */
  HAL_GPIO_WritePin(LCD_BL_CTRL_GPIO_Port, LCD_BL_CTRL_Pin, GPIO_PIN_RESET);

  /*Configure GPIO pin Output Level */
  HAL_GPIO_WritePin(LCD_DISP_GPIO_Port, LCD_DISP_Pin, GPIO_PIN_RESET);

  /*Configure GPIO pin Output Level */
  HAL_GPIO_WritePin(DHT11_DATA_GPIO_Port, DHT11_DATA_Pin, GPIO_PIN_SET);

  /*Configure GPIO pin : LCD_BL_CTRL_Pin */
  GPIO_InitStruct.Pin = LCD_BL_CTRL_Pin;
  GPIO_InitStruct.Mode = GPIO_MODE_OUTPUT_PP;
  GPIO_InitStruct.Pull = GPIO_NOPULL;
  GPIO_InitStruct.Speed = GPIO_SPEED_FREQ_LOW;
  HAL_GPIO_Init(LCD_BL_CTRL_GPIO_Port, &GPIO_InitStruct);

  /*Configure GPIO pin : LCD_DISP_Pin */
  GPIO_InitStruct.Pin = LCD_DISP_Pin;
  GPIO_InitStruct.Mode = GPIO_MODE_OUTPUT_PP;
  GPIO_InitStruct.Pull = GPIO_NOPULL;
  GPIO_InitStruct.Speed = GPIO_SPEED_FREQ_LOW;
  HAL_GPIO_Init(LCD_DISP_GPIO_Port, &GPIO_InitStruct);

  /*Configure GPIO pin : DHT11_DATA_Pin */
  GPIO_InitStruct.Pin = DHT11_DATA_Pin;
  GPIO_InitStruct.Mode = GPIO_MODE_OUTPUT_OD;
  GPIO_InitStruct.Pull = GPIO_NOPULL;
  GPIO_InitStruct.Speed = GPIO_SPEED_FREQ_LOW;
  HAL_GPIO_Init(DHT11_DATA_GPIO_Port, &GPIO_InitStruct);

}

 /* MPU Configuration */

void MPU_Config(void)
{
  MPU_Region_InitTypeDef MPU_InitStruct = {0};

  /* Disables the MPU */
  HAL_MPU_Disable();

  /** Initializes and configures the Region and the memory to be protected
  */
  MPU_InitStruct.Enable = MPU_REGION_ENABLE;
  MPU_InitStruct.Number = MPU_REGION_NUMBER0;
  MPU_InitStruct.BaseAddress = 0x0;
  MPU_InitStruct.Size = MPU_REGION_SIZE_4GB;
  MPU_InitStruct.SubRegionDisable = 0x87;
  MPU_InitStruct.TypeExtField = MPU_TEX_LEVEL0;
  MPU_InitStruct.AccessPermission = MPU_REGION_NO_ACCESS;
  MPU_InitStruct.DisableExec = MPU_INSTRUCTION_ACCESS_DISABLE;
  MPU_InitStruct.IsShareable = MPU_ACCESS_SHAREABLE;
  MPU_InitStruct.IsCacheable = MPU_ACCESS_NOT_CACHEABLE;
  MPU_InitStruct.IsBufferable = MPU_ACCESS_NOT_BUFFERABLE;

  HAL_MPU_ConfigRegion(&MPU_InitStruct);

  /** Initializes and configures the Region and the memory to be protected
  */
  MPU_InitStruct.Number = MPU_REGION_NUMBER1;
  MPU_InitStruct.BaseAddress = 0xC0000000;
  MPU_InitStruct.Size = MPU_REGION_SIZE_8MB;
  MPU_InitStruct.SubRegionDisable = 0x0;
  MPU_InitStruct.TypeExtField = MPU_TEX_LEVEL1;
  MPU_InitStruct.AccessPermission = MPU_REGION_FULL_ACCESS;
  MPU_InitStruct.IsShareable = MPU_ACCESS_NOT_SHAREABLE;

  HAL_MPU_ConfigRegion(&MPU_InitStruct);

  /** Initializes and configures the Region and the memory to be protected
  */
  MPU_InitStruct.Number = MPU_REGION_NUMBER2;
  MPU_InitStruct.BaseAddress = 0xA0000000;
  MPU_InitStruct.Size = MPU_REGION_SIZE_4KB;
  MPU_InitStruct.TypeExtField = MPU_TEX_LEVEL0;
  MPU_InitStruct.IsShareable = MPU_ACCESS_SHAREABLE;
  MPU_InitStruct.IsBufferable = MPU_ACCESS_BUFFERABLE;

  HAL_MPU_ConfigRegion(&MPU_InitStruct);
  /* Enables the MPU */
  HAL_MPU_Enable(MPU_PRIVILEGED_DEFAULT);

}

void Error_Handler(void)
{
  __disable_irq();
  while (1)
  {
  }
}
